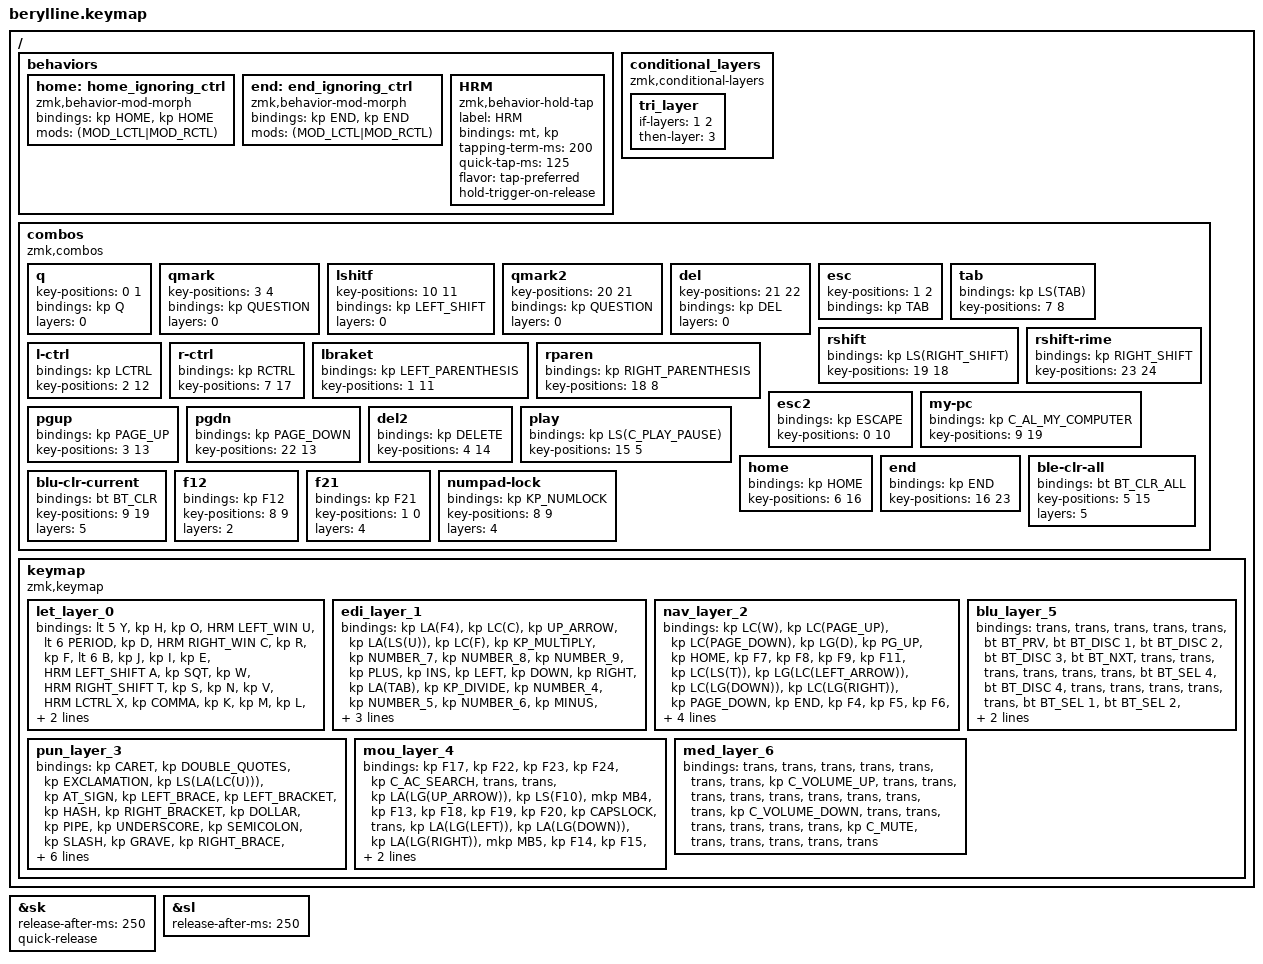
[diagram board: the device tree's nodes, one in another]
#include <behaviors.dtsi>
#include <dt-bindings/zmk/bt.h>
#include <dt-bindings/zmk/keys.h>
#include <dt-bindings/zmk/pointing.h>

/* Layers */

#define DEF 0
#define NAV 1
#define SYM 2
#define NUM 3

/* Shortcuts */

#define CUT LC(X)
#define COPY LC(C)
#define PASTE LC(V)
#define UNDO LC(Z)
#define ALL LC(A)
#define TOP LC(HOME)
#define BTM LC(END)

/* Behavior Settings */

&sk {
    release-after-ms = <250>;
    quick-release;
};

&sl { release-after-ms = <250>; };

/ {
    behaviors {
        home: home_ignoring_ctrl {
            compatible = "zmk,behavior-mod-morph";
            #binding-cells = <0>;
            bindings = <&kp HOME>, <&kp HOME>;

            mods = <(MOD_LCTL|MOD_RCTL)>;
        };

        end: end_ignoring_ctrl {
            compatible = "zmk,behavior-mod-morph";
            #binding-cells = <0>;
            bindings = <&kp END>, <&kp END>;

            mods = <(MOD_LCTL|MOD_RCTL)>;
        };

        HRM: HRM {
            compatible = "zmk,behavior-hold-tap";
            label = "HRM";
            bindings = <&mt>, <&kp>;

            #binding-cells = <2>;
            tapping-term-ms = <200>;
            quick-tap-ms = <125>;
            flavor = "tap-preferred";
            hold-trigger-on-release;
        };
    };

    conditional_layers {
        compatible = "zmk,conditional-layers";

        tri_layer {
            if-layers = <1 2>;
            then-layer = <3>;
        };
    };

    combos {
        compatible = "zmk,combos";

        /*                KEY POSITIONS

             0   1   2   3   4      5   6   7   8   9
            10  11  12  13  14     15  16  17  18  19
                20  21  22             23  24  25
                        26  27     28  29              */
        /*                KEY POSITIONS

             0   1   2   3   4      5   6   7   8   9
            10  11  12  13  14     15  16  17  18  19
                20  21  22             23  24  25
                        26  27     28  29              */
        /* some comments */

        q {
            key-positions = <0 1>;
            bindings = <&kp Q>;
            layers = <0>;
        };

        qmark {
            key-positions = <3 4>;
            bindings = <&kp QUESTION>;
            layers = <0>;
        };

        lshitf {
            key-positions = <10 11>;
            bindings = <&kp LEFT_SHIFT>;
            layers = <0>;
        };

        qmark2 {
            key-positions = <20 21>;
            bindings = <&kp QUESTION>;
            layers = <0>;
        };

        del {
            key-positions = <21 22>;
            bindings = <&kp DEL>;
            layers = <0>;
        };

        /* Brackets */
        /* Convenience */

        esc {
            key-positions = <1 2>;
            bindings = <&kp TAB>;
        };

        tab {
            bindings = <&kp LS(TAB)>;
            key-positions = <7 8>;
        };

        rshift {
            bindings = <&kp LS(RIGHT_SHIFT)>;
            key-positions = <19 18>;
        };

        rshift-rime {
            bindings = <&kp RIGHT_SHIFT>;
            key-positions = <23 24>;
        };

        l-ctrl {
            bindings = <&kp LCTRL>;
            key-positions = <2 12>;
        };

        r-ctrl {
            bindings = <&kp RCTRL>;
            key-positions = <7 17>;
        };

        lbraket {
            bindings = <&kp LEFT_PARENTHESIS>;
            key-positions = <1 11>;
        };

        rparen {
            bindings = <&kp RIGHT_PARENTHESIS>;
            key-positions = <18 8>;
        };

        esc2 {
            bindings = <&kp ESCAPE>;
            key-positions = <0 10>;
        };

        my-pc {
            bindings = <&kp C_AL_MY_COMPUTER>;
            key-positions = <9 19>;
        };

        pgup {
            bindings = <&kp PAGE_UP>;
            key-positions = <3 13>;
        };

        pgdn {
            bindings = <&kp PAGE_DOWN>;
            key-positions = <22 13>;
        };

        del2 {
            bindings = <&kp DELETE>;
            key-positions = <4 14>;
        };

        play {
            bindings = <&kp LS(C_PLAY_PAUSE)>;
            key-positions = <15 5>;
        };

        home {
            bindings = <&kp HOME>;
            key-positions = <6 16>;
        };

        end {
            bindings = <&kp END>;
            key-positions = <16 23>;
        };

        ble-clr-all {
            bindings = <&bt BT_CLR_ALL>;
            key-positions = <5 15>;
            layers = <5>;
        };

        blu-clr-current {
            bindings = <&bt BT_CLR>;
            key-positions = <9 19>;
            layers = <5>;
        };

        f12 {
            bindings = <&kp F12>;
            key-positions = <8 9>;
            layers = <2>;
        };

        f21 {
            bindings = <&kp F21>;
            key-positions = <1 0>;
            layers = <4>;
        };

        numpad-lock {
            bindings = <&kp KP_NUMLOCK>;
            key-positions = <8 9>;
            layers = <4>;
        };
    };

    keymap {
        compatible = "zmk,keymap";

        let_layer_0 {
            bindings = <
&lt 5 Y  &kp H  &kp O  &HRM LEFT_WIN U  &lt 6 PERIOD  &kp D  &HRM RIGHT_WIN C  &kp R  &kp F  &lt 6 B  &kp J  &kp I  &kp E  &HRM LEFT_SHIFT A  &kp SQT  &kp W  &HRM RIGHT_SHIFT T  &kp S  &kp N  &kp V  &HRM LCTRL X  &kp COMMA  &kp K  &kp M  &kp L  &HRM RCTRL P  &lt 1 BACKSPACE  &lt 2 ENTER  &lt 3 SPACE  &lt 4 DELETE
            >;
        };

        edi_layer_1 {
            bindings = <
&kp LA(F4)  &kp LC(C)  &kp UP_ARROW  &kp LA(LS(U))  &kp LC(F)  &kp KP_MULTIPLY  &kp NUMBER_7  &kp NUMBER_8  &kp NUMBER_9  &kp PLUS  &kp INS  &kp LEFT  &kp DOWN  &kp RIGHT  &kp LA(TAB)  &kp KP_DIVIDE  &kp NUMBER_4  &kp NUMBER_5  &kp NUMBER_6  &kp MINUS  &kp LC(X)  &kp LC(Z)  &kp LC(V)  &kp NUMBER_1  &kp NUMBER_2  &kp NUMBER_3  &trans  &kp K_PLAY_PAUSE  &kp EQUAL  &kp NUMBER_0
            >;
        };

        nav_layer_2 {
            bindings = <
&kp LC(W)  &kp LC(PAGE_UP)  &kp LC(PAGE_DOWN)  &kp LG(D)  &kp PG_UP  &kp HOME  &kp F7  &kp F8  &kp F9  &kp F11  &kp LC(LS(T))  &kp LG(LC(LEFT_ARROW))  &kp LC(LG(DOWN))  &kp LC(LG(RIGHT))  &kp PAGE_DOWN  &kp END  &kp F4  &kp F5  &kp F6  &kp F10  &kp LA(LS(ESCAPE))  &kp LC(LG(F4))  &kp LA(ESCAPE)  &kp F1  &kp F2  &kp F3  &kp C_REWIND  &trans  &kp LS(LA(G))  &kp LS(LA(C))
            >;
        };

        pun_layer_3 {
            bindings = <
&kp CARET  &kp DOUBLE_QUOTES  &kp EXCLAMATION  &kp LS(LA(LC(U)))  &kp AT_SIGN  &kp LEFT_BRACE  &kp LEFT_BRACKET  &kp HASH  &kp RIGHT_BRACKET  &kp DOLLAR  &kp PIPE  &kp UNDERSCORE  &kp SEMICOLON  &kp SLASH  &kp GRAVE  &kp RIGHT_BRACE  &kp LEFT_PARENTHESIS  &kp ASTERISK  &kp RIGHT_PARENTHESIS  &kp TILDE  &kp AMPERSAND  &kp PERCENT  &kp NON_US_BACKSLASH  &kp LESS_THAN  &kp EQUAL  &kp GREATER_THAN  &kp MINUS  &kp COLON  &trans  &kp C_FAST_FORWARD
            >;
        };

        mou_layer_4 {
            bindings = <
&kp F17  &kp F22  &kp F23  &kp F24  &kp C_AC_SEARCH  &trans  &trans  &kp LA(LG(UP_ARROW))  &kp LS(F10)  &mkp MB4  &kp F13  &kp F18  &kp F19  &kp F20  &kp CAPSLOCK  &trans  &kp LA(LG(LEFT))  &kp LA(LG(DOWN))  &kp LA(LG(RIGHT))  &mkp MB5  &kp F14  &kp F15  &kp F16  &mkp LCLK  &mkp MCLK  &mkp RCLK  &kp LA(LC(U))  &kp LA(LC(X))  &kp C_NEXT  &trans
            >;
        };

        blu_layer_5 {
            bindings = <
&trans  &trans  &trans  &trans  &trans  &bt BT_PRV  &bt BT_DISC 1  &bt BT_DISC 2  &bt BT_DISC 3  &bt BT_NXT  &trans  &trans  &trans  &trans  &trans  &trans  &bt BT_SEL 4  &bt BT_DISC 4  &trans  &trans  &trans  &trans  &trans  &bt BT_SEL 1  &bt BT_SEL 2  &bt BT_SEL 3  &trans  &trans  &bt BT_DISC 0  &bt BT_SEL 0
            >;
        };

        med_layer_6 {
            bindings = <
&trans  &trans  &trans  &trans  &trans  &trans  &trans  &kp C_VOLUME_UP  &trans  &trans  &trans  &trans  &trans  &trans  &trans  &trans  &trans  &kp C_VOLUME_DOWN  &trans  &trans  &trans  &trans  &trans  &trans  &kp C_MUTE  &trans  &trans  &trans  &trans  &trans
            >;
        };
    };
};
